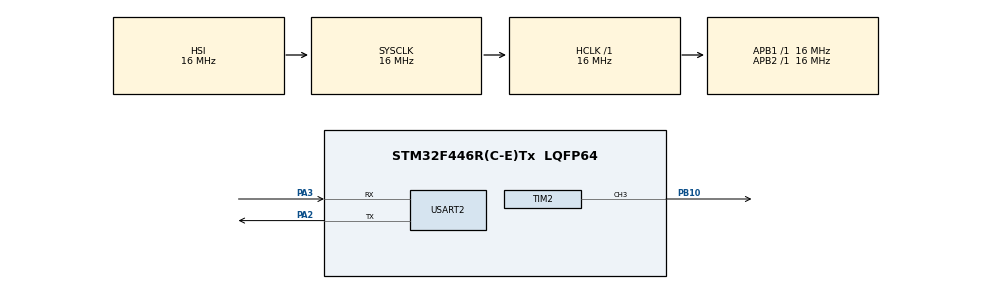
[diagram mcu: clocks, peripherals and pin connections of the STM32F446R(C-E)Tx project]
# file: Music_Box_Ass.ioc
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Mcu.Family=STM32F4
Mcu.Name=STM32F446R(C-E)Tx
Mcu.Package=LQFP64
NVIC.PriorityGroup=NVIC_PRIORITYGROUP_4
NVIC.USART2_IRQn=true\:0\:0\:false\:false\:true\:true\:true\:true
PA2.Mode=Asynchronous
PA2.Signal=USART2_TX
PA3.Mode=Asynchronous
PA3.Signal=USART2_RX
PB10.Signal=S_TIM2_CH3
ProjectManager.HeapSize=0x200
ProjectManager.StackSize=0x400
ProjectManager.TargetToolchain=STM32CubeIDE
RCC.AHBFreq_Value=16000000
RCC.APB1Freq_Value=16000000
RCC.APB1TimFreq_Value=16000000
RCC.APB2Freq_Value=16000000
RCC.APB2TimFreq_Value=16000000
RCC.CortexFreq_Value=16000000
RCC.HCLKFreq_Value=16000000
RCC.PLLN=168
RCC.SYSCLKFreq_VALUE=16000000
RCC.USBFreq_Value=84000000
RCC.VCOOutputFreq_Value=168000000
SH.S_TIM2_CH3.0=TIM2_CH3,PWM Generation3 CH3
TIM2.AutoReloadPreload=TIM_AUTORELOAD_PRELOAD_ENABLE
TIM2.Channel-PWM\ Generation3\ CH3=TIM_CHANNEL_3
TIM2.Period=8
TIM2.Prescaler=1999
TIM2.Pulse-PWM\ Generation3\ CH3=4
USART2.VirtualMode=VM_ASYNC
VP_TIM2_VS_ClockSourceINT.Mode=Internal
board=custom

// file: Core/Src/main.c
/* USER CODE BEGIN Header */
/**
 ******************************************************************************
 * @file           : main.c
 * @brief          : Main program body
 ******************************************************************************
 * @attention
 *
 * Copyright (c) 2024 STMicroelectronics.
 * All rights reserved.
 *
 * This software is licensed under terms that can be found in the LICENSE file
 * in the root directory of this software component.
 * If no LICENSE file comes with this software, it is provided AS-IS.
 *
 ******************************************************************************
 */
/* USER CODE END Header */
#include "main.h"
#include "tim.h"
#include "usart.h"
#include "gpio.h"
#include "speaker.h"

void SystemClock_Config(void);
/* USER CODE BEGIN PFP */

int _write(int fd, char *ptr, int len);

/* USER CODE END PFP */

/* USER CODE BEGIN 0 */
char uartBuffer[2];

/* USER CODE END 0 */

int main(void)
{

	/* MCU Configuration--------------------------------------------------------*/

	/* Reset of all peripherals, Initializes the Flash interface and the Systick. */
	HAL_Init();

	/* Configure the system clock */
	SystemClock_Config();

	/* Initialize all configured peripherals */
	MX_GPIO_Init();
	MX_TIM2_Init();
	MX_USART2_UART_Init();
	/* USER CODE BEGIN 2 */
	HAL_TIM_PWM_Start(&htim2, TIM_CHANNEL_3);

	/* USER CODE END 2 */

	/* Infinite loop */
	while (1)
	{

		/* USER CODE BEGIN 3 */
		if (HAL_UART_Receive(&huart2, (uint8_t*)uartBuffer, 2, HAL_MAX_DELAY) == HAL_OK)
		{
			HAL_UART_Transmit(&huart2,(uint8_t*)uartBuffer, 2, HAL_MAX_DELAY);
			char note = uartBuffer[0];  // The first byte is the note
			int octave = uartBuffer[1] - '1';  // The second byte is the octave, converted from char to integer

			uint32_t frequency = getNoteFrequency(note, octave);  // Get frequency from note and octave
			playNoteFrequency(frequency);  // Play the note
		}

	}
	/* USER CODE END 3 */
}

void SystemClock_Config(void)
{
	RCC_OscInitTypeDef RCC_OscInitStruct = {0};
	RCC_ClkInitTypeDef RCC_ClkInitStruct = {0};

	/** Configure the main internal regulator output voltage
	 */
	__HAL_RCC_PWR_CLK_ENABLE();
	__HAL_PWR_VOLTAGESCALING_CONFIG(PWR_REGULATOR_VOLTAGE_SCALE3);

	/** Initializes the RCC Oscillators according to the specified parameters
	 * in the RCC_OscInitTypeDef structure.
	 */
	RCC_OscInitStruct.OscillatorType = RCC_OSCILLATORTYPE_HSI;
	RCC_OscInitStruct.HSIState = RCC_HSI_ON;
	RCC_OscInitStruct.HSICalibrationValue = RCC_HSICALIBRATION_DEFAULT;
	RCC_OscInitStruct.PLL.PLLState = RCC_PLL_NONE;
	if (HAL_RCC_OscConfig(&RCC_OscInitStruct) != HAL_OK)
	{
		Error_Handler();
	}

	/** Initializes the CPU, AHB and APB buses clocks
	 */
	RCC_ClkInitStruct.ClockType = RCC_CLOCKTYPE_HCLK|RCC_CLOCKTYPE_SYSCLK
			|RCC_CLOCKTYPE_PCLK1|RCC_CLOCKTYPE_PCLK2;
	RCC_ClkInitStruct.SYSCLKSource = RCC_SYSCLKSOURCE_HSI;
	RCC_ClkInitStruct.AHBCLKDivider = RCC_SYSCLK_DIV1;
	RCC_ClkInitStruct.APB1CLKDivider = RCC_HCLK_DIV1;
	RCC_ClkInitStruct.APB2CLKDivider = RCC_HCLK_DIV1;

	if (HAL_RCC_ClockConfig(&RCC_ClkInitStruct, FLASH_LATENCY_0) != HAL_OK)
	{
		Error_Handler();
	}
}

/* USER CODE BEGIN 4 */

int _write(int fd, char *ptr, int len)
{
	HAL_StatusTypeDef status = HAL_UART_Transmit(&huart2, (uint8_t*)ptr, len, HAL_MAX_DELAY);
	return (status == HAL_OK) ? len : -1;
}

/* USER CODE END 4 */

void Error_Handler(void)
{
	__disable_irq();
	while (1)
	{
	}
}
